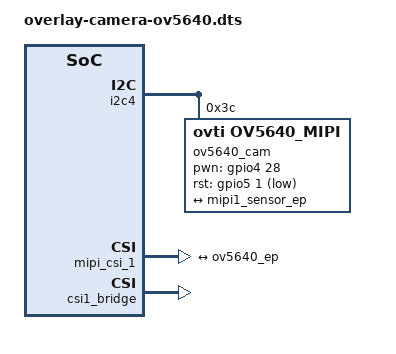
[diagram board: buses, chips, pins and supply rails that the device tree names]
/*
 * Copyright (C) 2023 AVNET Integrated, MSC Technologies GmbH
 *
 * This program is free software; you can redistribute it and/or
 * modify it under the terms of the GNU General Public License as
 * published by the Free Software Foundation version 2.
 *
 * This program is distributed "as is" WITHOUT ANY WARRANTY of any
 * kind, whether express or implied; without even the implied warranty
 * of MERCHANTABILITY or FITNESS FOR A PARTICULAR PURPOSE.  See the
 * GNU General Public License for more details.
 */

/dts-v1/;
/plugin/;

#include <dt-bindings/clock/imx8mm-clock.h>
#include <dt-bindings/gpio/gpio.h>
#include "../../freescale/imx8mm-pinfunc.h"

/ {
	fragment@9000 {
		target = <&i2c4>;
		__overlay__ {
			#address-cells = <1>;
			#size-cells = <0>;
			ov5640_cam: ov5640_mipi@3c {
				pinctrl-names = "default";
				pinctrl-0 = <&pinctrl_ov5640>;
				compatible = "ovti,ov5640_mipi";
				reg = <0x3c>;
				clocks = <&clk IMX8MM_CLK_CLKOUT2>;
				clock-names = "csi_mclk";
				assigned-clocks = <&clk IMX8MM_CLK_CLKOUT2_SEL>;
				assigned-clock-parents = <&clk IMX8MM_CLK_24M>;
				assigned-clock-rates = <24000000>;
				csi_id = <0>;
				pwn-gpios = <&gpio4 28 GPIO_ACTIVE_HIGH>;
				rst-gpios = <&gpio5  1 GPIO_ACTIVE_LOW>;
				mclk = <24000000>;
				mclk_source = <0>;
				status = "okay";
				port {
					ov5640_ep: endpoint {
						remote-endpoint = <&mipi1_sensor_ep>;
					};
				};
			};
		};
	};

	fragment@9001 {
		target = <&mipi_csi_1>;
		__overlay__ {
			#address-cells = <1>;
			#size-cells = <0>;
			status = "okay";
			port {
				mipi1_sensor_ep: endpoint@1 {
					remote-endpoint = <&ov5640_ep>;
					data-lanes = <2>;
					csis-hs-settle = <13>;
					csis-clk-settle = <2>;
					csis-wclk;
				};
			};
		};
	};

	fragment@9002 {
		target = <&csi1_bridge>;
		__overlay__ {
			status = "okay";
		};
	};
	fragment@9003 {
		target = <&iomuxc>;
		__overlay__ {
		        osm-imx8mm {
				pinctrl_ov5640: ov5640grp {
					fsl,pins = <
						MX8MM_IOMUXC_SAI3_RXFS_GPIO4_IO28	0x40000019	/* CAM_PWR  */
						MX8MM_IOMUXC_SAI3_TXD_GPIO5_IO1		0x40000019	/* CAM_RST# */
					>;
				};
			};
		};
	};
};
